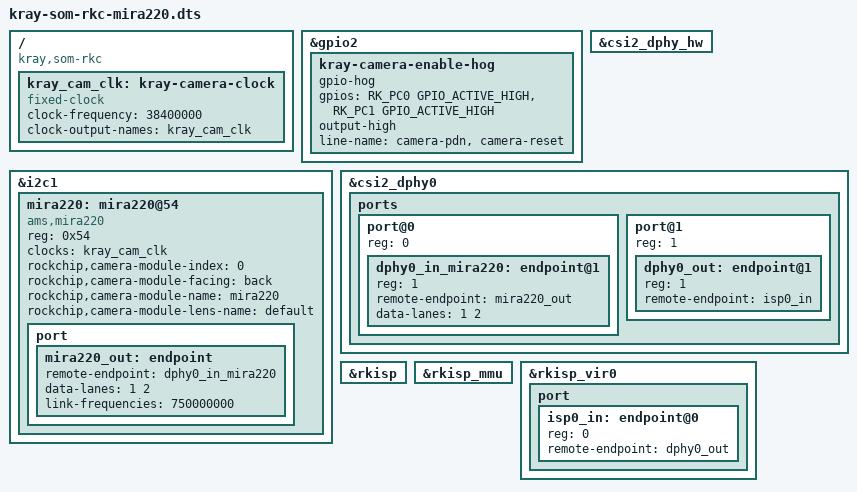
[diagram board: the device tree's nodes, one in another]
// SPDX-License-Identifier: (GPL-2.0+ OR MIT)
/*
 * Kray-SoM-RKC: ams Mira220 global shutter camera module (2.2 MP, NIR-enhanced) on the CSI connector. Vendor kernel only.
 *
 *   /boot/armbianEnv.txt:  overlays=kray-som-rkc-mira220
 *
 * Raspberry Pi's mira220 driver, backported (built in, userpatches/camera/
 * rpi_mira220). Sensor on I2C1 at 0x54, two MIPI CSI-2 lanes at 750 MHz
 * (1500 Mbit/s per lane), 38.4 MHz oscillator on the module. 1600x1400,
 * 12-bit Bayer. Camera power-down (GPIO2_C0) and reset (GPIO2_C1) are held
 * high.
 */

/dts-v1/;
/plugin/;

#include <dt-bindings/gpio/gpio.h>
#include <dt-bindings/pinctrl/rockchip.h>

/ {
	compatible = "kray,som-rkc", "rockchip,rk3566";

	fragment@0 {
		target-path = "/";
		__overlay__ {
			kray_cam_clk: kray-camera-clock {
				compatible = "fixed-clock";
				#clock-cells = <0>;
				clock-frequency = <38400000>;
				clock-output-names = "kray_cam_clk";
			};
		};
	};

	fragment@1 {
		target = <&gpio2>;
		__overlay__ {
			kray-camera-enable-hog {
				gpio-hog;
				/* GPIO2_C0: power-down (PDN), GPIO2_C1: reset */
				gpios = <RK_PC0 GPIO_ACTIVE_HIGH>, <RK_PC1 GPIO_ACTIVE_HIGH>;
				output-high;
				line-name = "camera-pdn", "camera-reset";
			};
		};
	};

	fragment@2 {
		target = <&i2c1>;
		__overlay__ {
			status = "okay";
			#address-cells = <1>;
			#size-cells = <0>;

			mira220: mira220@54 {
				compatible = "ams,mira220";
				reg = <0x54>;
				clocks = <&kray_cam_clk>;
				rockchip,camera-module-index = <0>;
				rockchip,camera-module-facing = "back";
				rockchip,camera-module-name = "mira220";
				rockchip,camera-module-lens-name = "default";

				port {
					mira220_out: endpoint {
						remote-endpoint = <&dphy0_in_mira220>;
						data-lanes = <1 2>;
						link-frequencies = /bits/ 64 <750000000>;
					};
				};
			};
		};
	};

	fragment@3 {
		target = <&csi2_dphy_hw>;
		__overlay__ {
			status = "okay";
		};
	};

	fragment@4 {
		target = <&csi2_dphy0>;
		__overlay__ {
			status = "okay";

			ports {
				#address-cells = <1>;
				#size-cells = <0>;

				port@0 {
					reg = <0>;
					#address-cells = <1>;
					#size-cells = <0>;

					dphy0_in_mira220: endpoint@1 {
						reg = <1>;
						remote-endpoint = <&mira220_out>;
						data-lanes = <1 2>;
					};
				};

				port@1 {
					reg = <1>;
					#address-cells = <1>;
					#size-cells = <0>;

					dphy0_out: endpoint@1 {
						reg = <1>;
						remote-endpoint = <&isp0_in>;
					};
				};
			};
		};
	};

	fragment@5 {
		target = <&rkisp>;
		__overlay__ {
			status = "okay";
		};
	};

	fragment@6 {
		target = <&rkisp_mmu>;
		__overlay__ {
			status = "okay";
		};
	};

	fragment@7 {
		target = <&rkisp_vir0>;
		__overlay__ {
			status = "okay";

			port {
				#address-cells = <1>;
				#size-cells = <0>;

				isp0_in: endpoint@0 {
					reg = <0>;
					remote-endpoint = <&dphy0_out>;
				};
			};
		};
	};
};
